# STM32F102 register map
File version: 1.1
CPU: CM3 r1p1, little endian, no MPU, no FPU, 4 interrupt priority bits
Registers are 32-bit, read-write, reset 0x0 unless marked. A register's access mark holds for its fields unless they carry their own. Offsets are from the block's base; [hi:lo] are bit positions; {n}, {i} and the like mark numbered series.

## OTG_FS_PWRCLK — USB on the go full speed
Base 0x50000E00
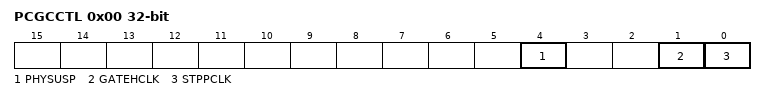
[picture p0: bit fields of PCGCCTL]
0x00 PCGCCTL — OTG_FS power and clock gating control register
  [4] PHYSUSP — PHY Suspended
  [1] GATEHCLK
  [0] STPPCLK — Stop PHY clock

## TIM6 — Basic timer
Base 0x40001000
Same registers: TIM7 0x40001400
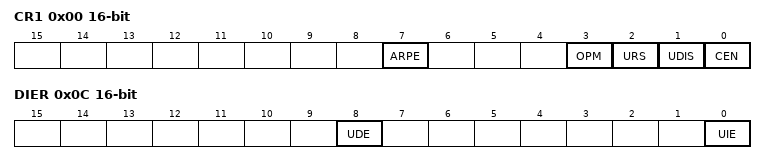
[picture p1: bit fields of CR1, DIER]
0x00 CR1 16-bit — control register 1
  [7] ARPE — Auto-reload preload enable
    0=Disabled (TIMx_APRR register is not buffered); 1=Enabled (TIMx_APRR register is buffered)
  [3] OPM — One-pulse mode
    0=Disabled (Counter is not stopped at update event); 1=Enabled (Counter stops counting at the next update event (clearing the CEN bit))
  [2] URS — Update request source
    0=AnyEvent (Any of counter overflow/underflow, setting UG, or update through slave mode, generates an update interrupt or DMA request); 1=CounterOnly (Only counter overflow/underflow generates an update interrupt or DMA request)
  [1] UDIS — Update disable
    0=Enabled (Update event enabled); 1=Disabled (Update event disabled)
  [0] CEN — Counter enable
    0=Disabled (Counter disabled); 1=Enabled (Counter enabled)
0x04 CR2 16-bit — control register 2
  [6:4] MMS — Master mode selection
    0=Reset (Use UG bit from TIMx_EGR register); 1=Enable (Use CNT bit from TIMx_CEN register); 2=Update (Use the update event)
0x0C DIER 16-bit — DMA/Interrupt enable register
  [8] UDE — Update DMA request enable
    0=Disabled (Update DMA request disabled); 1=Enabled (Update DMA request enabled)
  [0] UIE — Update interrupt enable
    0=Disabled (Update interrupt disabled); 1=Enabled (Update interrupt enabled)
0x10 SR 16-bit — status register
  [0] UIF write-0-clears — Update interrupt flag
    on read: 0=NoUpdateOccurred; 1=UpdatePending (Update interrupt pending) | on write: 0=Clear flag
0x14 EGR 16-bit wo — event generation register
  [0] UG — Update generation
    1=Update (Re-initializes the timer counter and generates an update of the registers.)
0x24 CNT 16-bit — counter
  [15:0] CNT — Low counter value
0x28 PSC 16-bit — prescaler
  [15:0] PSC — Prescaler value
0x2C ARR 16-bit reset 0xFFFF — auto-reload register
  [15:0] ARR — Low Auto-reload value

## NVIC — Nested Vectored Interrupt Controller
Base 0xE000E100
0x00 ISER0 — Interrupt Set-Enable Register
  [31:0] SETENA
0x04 ISER1 — Interrupt Set-Enable Register
  [31:0] SETENA
0x80 ICER0 — Interrupt Clear-Enable Register
  [31:0] CLRENA
0x84 ICER1 — Interrupt Clear-Enable Register
  [31:0] CLRENA
0x100 ISPR0 — Interrupt Set-Pending Register
  [31:0] SETPEND
0x104 ISPR1 — Interrupt Set-Pending Register
  [31:0] SETPEND
0x180 ICPR0 — Interrupt Clear-Pending Register
  [31:0] CLRPEND
0x184 ICPR1 — Interrupt Clear-Pending Register
  [31:0] CLRPEND
0x200 IABR0 ro — Interrupt Active Bit Register
  [31:0] ACTIVE
0x204 IABR1 ro — Interrupt Active Bit Register
  [31:0] ACTIVE
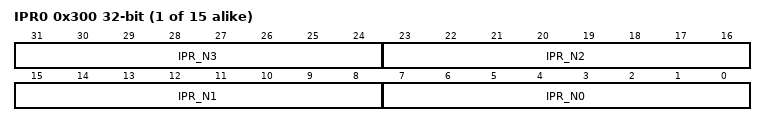
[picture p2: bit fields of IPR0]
{0x300+4i} IPR{i} (i=0..14) — Interrupt Priority Register
  [8n+7:8n] IPR_N{n} (n=0..3)

## MPU — Memory protection unit
Base 0xE000ED90
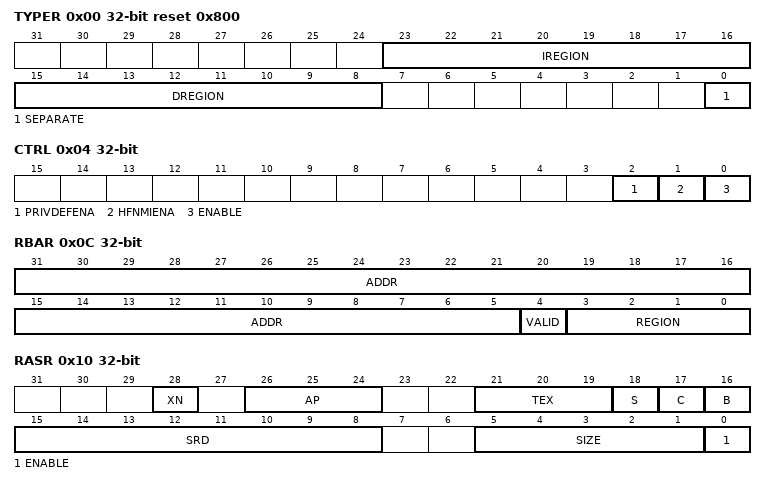
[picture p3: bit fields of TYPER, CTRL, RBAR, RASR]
0x00 TYPER ro reset 0x800 — MPU type register
  [23:16] IREGION — Number of MPU instruction regions
  [15:8] DREGION — Number of MPU data regions
  [0] SEPARATE — Separate flag
0x04 CTRL ro — MPU control register
  [2] PRIVDEFENA — Enable priviliged software access to default memory map
  [1] HFNMIENA — Enables the operation of MPU during hard fault
  [0] ENABLE — Enables the MPU
0x08 RNR — MPU region number register
  [7:0] REGION — MPU region
0x0C RBAR — MPU region base address register
  [31:5] ADDR — Region base address field
  [4] VALID — MPU region number valid
  [3:0] REGION — MPU region field
0x10 RASR — MPU region attribute and size register
  [28] XN — Instruction access disable bit
  [26:24] AP — Access permission
  [21:19] TEX — memory attribute
  [18] S — Shareable memory attribute
  [17] C — memory attribute
  [16] B — memory attribute
  [15:8] SRD — Subregion disable bits
  [5:1] SIZE — Size of the MPU protection region
  [0] ENABLE — Region enable bit.

## SCB_ACTRL — System control block ACTLR
Base 0xE000E008
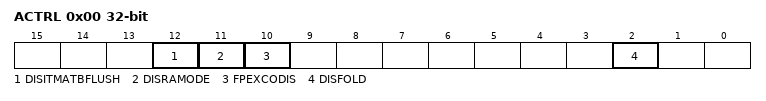
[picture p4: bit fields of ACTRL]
0x00 ACTRL — Auxiliary control register
  [12] DISITMATBFLUSH, [11] DISRAMODE, [10] FPEXCODIS, [2] DISFOLD

## NVIC_STIR — Nested vectored interrupt controller
Base 0xE000EF00
0x00 STIR — Software trigger interrupt register
  [8:0] INTID — Software generated interrupt ID

## STK — SysTick timer
Base 0xE000E010
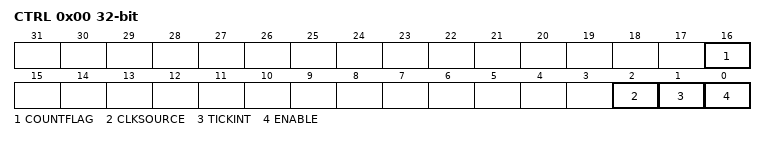
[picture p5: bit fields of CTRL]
0x00 CTRL — SysTick control and status register
  [16] COUNTFLAG
  [2] CLKSOURCE — Clock source selection
  [1] TICKINT — SysTick exception request enable
  [0] ENABLE — Counter enable
0x04 LOAD_ — SysTick reload value register
  [23:0] RELOAD — RELOAD value
0x08 VAL — SysTick current value register
  [23:0] CURRENT — Current counter value
0x0C CALIB — SysTick calibration value register
  [23:0] TENMS — Calibration value
